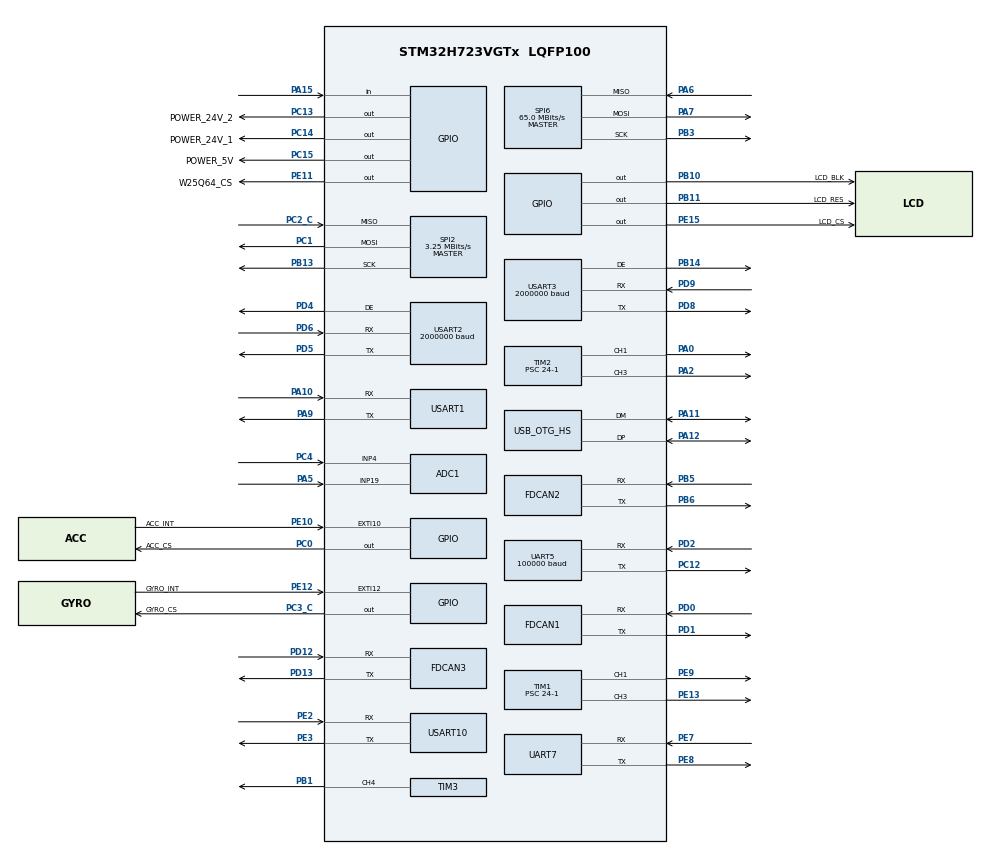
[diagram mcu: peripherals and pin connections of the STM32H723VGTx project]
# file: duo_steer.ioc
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ADC1.Channel-0\#ChannelRegularConversion=ADC_CHANNEL_19
ADC1.Channel-1\#ChannelRegularConversion=ADC_CHANNEL_4
ADC1.ContinuousConvMode=ENABLE
ADC1.ConversionDataManagement=ADC_CONVERSIONDATA_DMA_CIRCULAR
ADC1.NbrOfConversion=2
ADC1.NbrOfConversionFlag=1
ADC1.OffsetNumber-0\#ChannelRegularConversion=ADC_OFFSET_NONE
ADC1.OffsetNumber-1\#ChannelRegularConversion=ADC_OFFSET_NONE
ADC1.OffsetSignedSaturation-0\#ChannelRegularConversion=DISABLE
ADC1.OffsetSignedSaturation-1\#ChannelRegularConversion=DISABLE
ADC1.Rank-0\#ChannelRegularConversion=1
ADC1.Rank-1\#ChannelRegularConversion=2
ADC1.SamplingTime-0\#ChannelRegularConversion=ADC_SAMPLETIME_32CYCLES_5
ADC1.SamplingTime-1\#ChannelRegularConversion=ADC_SAMPLETIME_32CYCLES_5
ADC1.master=1
Bdma.Request0=SPI6_RX
Bdma.Request1=SPI6_TX
Bdma.RequestsNb=2
Bdma.SPI6_RX.0.Direction=DMA_PERIPH_TO_MEMORY
Bdma.SPI6_RX.0.EventEnable=DISABLE
Bdma.SPI6_RX.0.Instance=BDMA_Channel0
Bdma.SPI6_RX.0.MemDataAlignment=DMA_MDATAALIGN_BYTE
Bdma.SPI6_RX.0.MemInc=DMA_MINC_ENABLE
Bdma.SPI6_RX.0.Mode=DMA_NORMAL
Bdma.SPI6_RX.0.PeriphDataAlignment=DMA_PDATAALIGN_BYTE
Bdma.SPI6_RX.0.PeriphInc=DMA_PINC_DISABLE
Bdma.SPI6_RX.0.Polarity=HAL_DMAMUX_REQ_GEN_RISING
Bdma.SPI6_RX.0.Priority=DMA_PRIORITY_LOW
Bdma.SPI6_RX.0.RequestNumber=1
Bdma.SPI6_RX.0.SignalID=NONE
Bdma.SPI6_RX.0.SyncEnable=DISABLE
Bdma.SPI6_RX.0.SyncPolarity=HAL_DMAMUX_SYNC_NO_EVENT
Bdma.SPI6_RX.0.SyncRequestNumber=1
Bdma.SPI6_RX.0.SyncSignalID=NONE
Bdma.SPI6_TX.1.Direction=DMA_MEMORY_TO_PERIPH
Bdma.SPI6_TX.1.EventEnable=DISABLE
Bdma.SPI6_TX.1.Instance=BDMA_Channel1
Bdma.SPI6_TX.1.MemDataAlignment=DMA_MDATAALIGN_BYTE
Bdma.SPI6_TX.1.MemInc=DMA_MINC_ENABLE
Bdma.SPI6_TX.1.Mode=DMA_NORMAL
Bdma.SPI6_TX.1.PeriphDataAlignment=DMA_PDATAALIGN_BYTE
Bdma.SPI6_TX.1.PeriphInc=DMA_PINC_DISABLE
Bdma.SPI6_TX.1.Polarity=HAL_DMAMUX_REQ_GEN_RISING
Bdma.SPI6_TX.1.Priority=DMA_PRIORITY_LOW
Bdma.SPI6_TX.1.RequestNumber=1
Bdma.SPI6_TX.1.SignalID=NONE
Bdma.SPI6_TX.1.SyncEnable=DISABLE
Bdma.SPI6_TX.1.SyncPolarity=HAL_DMAMUX_SYNC_NO_EVENT
Bdma.SPI6_TX.1.SyncRequestNumber=1
Bdma.SPI6_TX.1.SyncSignalID=NONE
CORTEX_M7.CPU_DCache=Enabled
CORTEX_M7.CPU_ICache=Enabled
CORTEX_M7.default_mode_Activation=1
DAC1.DAC_Channel-DAC_OUT2_Int=DAC_CHANNEL_2
Dma.ADC1.0.Direction=DMA_PERIPH_TO_MEMORY
Dma.ADC1.0.EventEnable=DISABLE
Dma.ADC1.0.FIFOMode=DMA_FIFOMODE_DISABLE
Dma.ADC1.0.Instance=DMA1_Stream0
Dma.ADC1.0.MemDataAlignment=DMA_MDATAALIGN_HALFWORD
Dma.ADC1.0.MemInc=DMA_MINC_ENABLE
Dma.ADC1.0.Mode=DMA_CIRCULAR
Dma.ADC1.0.PeriphDataAlignment=DMA_PDATAALIGN_HALFWORD
Dma.ADC1.0.PeriphInc=DMA_PINC_DISABLE
Dma.ADC1.0.Polarity=HAL_DMAMUX_REQ_GEN_RISING
Dma.ADC1.0.Priority=DMA_PRIORITY_LOW
Dma.ADC1.0.RequestNumber=1
Dma.ADC1.0.SignalID=NONE
Dma.ADC1.0.SyncEnable=DISABLE
Dma.ADC1.0.SyncPolarity=HAL_DMAMUX_SYNC_NO_EVENT
Dma.ADC1.0.SyncRequestNumber=1
Dma.ADC1.0.SyncSignalID=NONE
Dma.Request0=ADC1
Dma.Request1=SPI2_RX
Dma.Request10=USART3_RX
Dma.Request11=USART3_TX
Dma.Request12=USART10_RX
Dma.Request13=USART10_TX
Dma.Request2=SPI2_TX
Dma.Request3=UART5_RX
Dma.Request4=UART7_RX
Dma.Request5=UART7_TX
Dma.Request6=USART1_RX
Dma.Request7=USART1_TX
Dma.Request8=USART2_RX
Dma.Request9=USART2_TX
Dma.SPI2_RX.1.Direction=DMA_PERIPH_TO_MEMORY
Dma.SPI2_RX.1.EventEnable=DISABLE
Dma.SPI2_RX.1.FIFOMode=DMA_FIFOMODE_DISABLE
Dma.SPI2_RX.1.Instance=DMA1_Stream1
Dma.SPI2_RX.1.MemDataAlignment=DMA_MDATAALIGN_BYTE
Dma.SPI2_RX.1.MemInc=DMA_MINC_ENABLE
Dma.SPI2_RX.1.Mode=DMA_NORMAL
Dma.SPI2_RX.1.PeriphDataAlignment=DMA_PDATAALIGN_BYTE
Dma.SPI2_RX.1.PeriphInc=DMA_PINC_DISABLE
Dma.SPI2_RX.1.Polarity=HAL_DMAMUX_REQ_GEN_RISING
Dma.SPI2_RX.1.Priority=DMA_PRIORITY_LOW
Dma.SPI2_RX.1.RequestNumber=1
Dma.SPI2_RX.1.SignalID=NONE
Dma.SPI2_RX.1.SyncEnable=DISABLE
Dma.SPI2_RX.1.SyncPolarity=HAL_DMAMUX_SYNC_NO_EVENT
Dma.SPI2_RX.1.SyncRequestNumber=1
Dma.SPI2_RX.1.SyncSignalID=NONE
Dma.SPI2_TX.2.Direction=DMA_MEMORY_TO_PERIPH
Dma.SPI2_TX.2.EventEnable=DISABLE
Dma.SPI2_TX.2.FIFOMode=DMA_FIFOMODE_DISABLE
Dma.SPI2_TX.2.Instance=DMA1_Stream2
Dma.SPI2_TX.2.MemDataAlignment=DMA_MDATAALIGN_BYTE
Dma.SPI2_TX.2.MemInc=DMA_MINC_ENABLE
Dma.SPI2_TX.2.Mode=DMA_NORMAL
Dma.SPI2_TX.2.PeriphDataAlignment=DMA_PDATAALIGN_BYTE
Dma.SPI2_TX.2.PeriphInc=DMA_PINC_DISABLE
Dma.SPI2_TX.2.Polarity=HAL_DMAMUX_REQ_GEN_RISING
Dma.SPI2_TX.2.Priority=DMA_PRIORITY_LOW
Dma.SPI2_TX.2.RequestNumber=1
Dma.SPI2_TX.2.SignalID=NONE
Dma.SPI2_TX.2.SyncEnable=DISABLE
Dma.SPI2_TX.2.SyncPolarity=HAL_DMAMUX_SYNC_NO_EVENT
Dma.SPI2_TX.2.SyncRequestNumber=1
Dma.SPI2_TX.2.SyncSignalID=NONE
Dma.UART5_RX.3.Direction=DMA_PERIPH_TO_MEMORY
Dma.UART5_RX.3.EventEnable=DISABLE
Dma.UART5_RX.3.FIFOMode=DMA_FIFOMODE_DISABLE
Dma.UART5_RX.3.Instance=DMA1_Stream3
Dma.UART5_RX.3.MemDataAlignment=DMA_MDATAALIGN_BYTE
Dma.UART5_RX.3.MemInc=DMA_MINC_ENABLE
Dma.UART5_RX.3.Mode=DMA_CIRCULAR
Dma.UART5_RX.3.PeriphDataAlignment=DMA_PDATAALIGN_BYTE
Dma.UART5_RX.3.PeriphInc=DMA_PINC_DISABLE
Dma.UART5_RX.3.Polarity=HAL_DMAMUX_REQ_GEN_RISING
Dma.UART5_RX.3.Priority=DMA_PRIORITY_LOW
Dma.UART5_RX.3.RequestNumber=1
Dma.UART5_RX.3.SignalID=NONE
Dma.UART5_RX.3.SyncEnable=DISABLE
Dma.UART5_RX.3.SyncPolarity=HAL_DMAMUX_SYNC_NO_EVENT
Dma.UART5_RX.3.SyncRequestNumber=1
Dma.UART5_RX.3.SyncSignalID=NONE
Dma.UART7_RX.4.Direction=DMA_PERIPH_TO_MEMORY
Dma.UART7_RX.4.EventEnable=DISABLE
Dma.UART7_RX.4.FIFOMode=DMA_FIFOMODE_DISABLE
Dma.UART7_RX.4.Instance=DMA1_Stream4
Dma.UART7_RX.4.MemDataAlignment=DMA_MDATAALIGN_BYTE
Dma.UART7_RX.4.MemInc=DMA_MINC_ENABLE
Dma.UART7_RX.4.Mode=DMA_CIRCULAR
Dma.UART7_RX.4.PeriphDataAlignment=DMA_PDATAALIGN_BYTE
Dma.UART7_RX.4.PeriphInc=DMA_PINC_DISABLE
Dma.UART7_RX.4.Polarity=HAL_DMAMUX_REQ_GEN_RISING
Dma.UART7_RX.4.Priority=DMA_PRIORITY_LOW
Dma.UART7_RX.4.RequestNumber=1
Dma.UART7_RX.4.SignalID=NONE
Dma.UART7_RX.4.SyncEnable=DISABLE
Dma.UART7_RX.4.SyncPolarity=HAL_DMAMUX_SYNC_NO_EVENT
Dma.UART7_RX.4.SyncRequestNumber=1
Dma.UART7_RX.4.SyncSignalID=NONE
Dma.UART7_TX.5.Direction=DMA_MEMORY_TO_PERIPH
Dma.UART7_TX.5.EventEnable=DISABLE
Dma.UART7_TX.5.FIFOMode=DMA_FIFOMODE_DISABLE
Dma.UART7_TX.5.Instance=DMA1_Stream5
Dma.UART7_TX.5.MemDataAlignment=DMA_MDATAALIGN_BYTE
Dma.UART7_TX.5.MemInc=DMA_MINC_ENABLE
Dma.UART7_TX.5.Mode=DMA_NORMAL
Dma.UART7_TX.5.PeriphDataAlignment=DMA_PDATAALIGN_BYTE
Dma.UART7_TX.5.PeriphInc=DMA_PINC_DISABLE
Dma.UART7_TX.5.Polarity=HAL_DMAMUX_REQ_GEN_RISING
Dma.UART7_TX.5.Priority=DMA_PRIORITY_LOW
Dma.UART7_TX.5.RequestNumber=1
Dma.UART7_TX.5.SignalID=NONE
Dma.UART7_TX.5.SyncEnable=DISABLE
Dma.UART7_TX.5.SyncPolarity=HAL_DMAMUX_SYNC_NO_EVENT
Dma.UART7_TX.5.SyncRequestNumber=1
Dma.UART7_TX.5.SyncSignalID=NONE
Dma.USART10_RX.12.Direction=DMA_PERIPH_TO_MEMORY
Dma.USART10_RX.12.EventEnable=DISABLE
Dma.USART10_RX.12.FIFOMode=DMA_FIFOMODE_DISABLE
Dma.USART10_RX.12.Instance=DMA2_Stream4
Dma.USART10_RX.12.MemDataAlignment=DMA_MDATAALIGN_BYTE
Dma.USART10_RX.12.MemInc=DMA_MINC_ENABLE
Dma.USART10_RX.12.Mode=DMA_CIRCULAR
Dma.USART10_RX.12.PeriphDataAlignment=DMA_PDATAALIGN_BYTE
Dma.USART10_RX.12.PeriphInc=DMA_PINC_DISABLE
Dma.USART10_RX.12.Polarity=HAL_DMAMUX_REQ_GEN_RISING
Dma.USART10_RX.12.Priority=DMA_PRIORITY_LOW
Dma.USART10_RX.12.RequestNumber=1
Dma.USART10_RX.12.SignalID=NONE
Dma.USART10_RX.12.SyncEnable=DISABLE
Dma.USART10_RX.12.SyncPolarity=HAL_DMAMUX_SYNC_NO_EVENT
Dma.USART10_RX.12.SyncRequestNumber=1
Dma.USART10_RX.12.SyncSignalID=NONE
Dma.USART10_TX.13.Direction=DMA_MEMORY_TO_PERIPH
Dma.USART10_TX.13.EventEnable=DISABLE
Dma.USART10_TX.13.FIFOMode=DMA_FIFOMODE_DISABLE
Dma.USART10_TX.13.Instance=DMA2_Stream5
Dma.USART10_TX.13.MemDataAlignment=DMA_MDATAALIGN_BYTE
Dma.USART10_TX.13.MemInc=DMA_MINC_ENABLE
Dma.USART10_TX.13.Mode=DMA_NORMAL
Dma.USART10_TX.13.PeriphDataAlignment=DMA_PDATAALIGN_BYTE
Dma.USART10_TX.13.PeriphInc=DMA_PINC_DISABLE
Dma.USART10_TX.13.Polarity=HAL_DMAMUX_REQ_GEN_RISING
Dma.USART10_TX.13.Priority=DMA_PRIORITY_LOW
Dma.USART10_TX.13.RequestNumber=1
Dma.USART10_TX.13.SignalID=NONE
Dma.USART10_TX.13.SyncEnable=DISABLE
Dma.USART10_TX.13.SyncPolarity=HAL_DMAMUX_SYNC_NO_EVENT
Dma.USART10_TX.13.SyncRequestNumber=1
Dma.USART10_TX.13.SyncSignalID=NONE
Dma.USART1_RX.6.Direction=DMA_PERIPH_TO_MEMORY
Dma.USART1_RX.6.EventEnable=DISABLE
Dma.USART1_RX.6.FIFOMode=DMA_FIFOMODE_DISABLE
Dma.USART1_RX.6.Instance=DMA1_Stream6
Dma.USART1_RX.6.MemDataAlignment=DMA_MDATAALIGN_BYTE
Dma.USART1_RX.6.MemInc=DMA_MINC_ENABLE
Dma.USART1_RX.6.Mode=DMA_CIRCULAR
Dma.USART1_RX.6.PeriphDataAlignment=DMA_PDATAALIGN_BYTE
Dma.USART1_RX.6.PeriphInc=DMA_PINC_DISABLE
Dma.USART1_RX.6.Polarity=HAL_DMAMUX_REQ_GEN_RISING
Dma.USART1_RX.6.Priority=DMA_PRIORITY_LOW
Dma.USART1_RX.6.RequestNumber=1
Dma.USART1_RX.6.SignalID=NONE
Dma.USART1_RX.6.SyncEnable=DISABLE
Dma.USART1_RX.6.SyncPolarity=HAL_DMAMUX_SYNC_NO_EVENT
Dma.USART1_RX.6.SyncRequestNumber=1
Dma.USART1_RX.6.SyncSignalID=NONE
Dma.USART1_TX.7.Direction=DMA_MEMORY_TO_PERIPH
Dma.USART1_TX.7.EventEnable=DISABLE
Dma.USART1_TX.7.FIFOMode=DMA_FIFOMODE_DISABLE
Dma.USART1_TX.7.Instance=DMA1_Stream7
Dma.USART1_TX.7.MemDataAlignment=DMA_MDATAALIGN_BYTE
Dma.USART1_TX.7.MemInc=DMA_MINC_ENABLE
Dma.USART1_TX.7.Mode=DMA_NORMAL
Dma.USART1_TX.7.PeriphDataAlignment=DMA_PDATAALIGN_BYTE
Dma.USART1_TX.7.PeriphInc=DMA_PINC_DISABLE
Dma.USART1_TX.7.Polarity=HAL_DMAMUX_REQ_GEN_RISING
Dma.USART1_TX.7.Priority=DMA_PRIORITY_LOW
Dma.USART1_TX.7.RequestNumber=1
Dma.USART1_TX.7.SignalID=NONE
Dma.USART1_TX.7.SyncEnable=DISABLE
Dma.USART1_TX.7.SyncPolarity=HAL_DMAMUX_SYNC_NO_EVENT
Dma.USART1_TX.7.SyncRequestNumber=1
Dma.USART1_TX.7.SyncSignalID=NONE
Dma.USART2_RX.8.Direction=DMA_PERIPH_TO_MEMORY
Dma.USART2_RX.8.EventEnable=DISABLE
Dma.USART2_RX.8.FIFOMode=DMA_FIFOMODE_DISABLE
Dma.USART2_RX.8.Instance=DMA2_Stream0
Dma.USART2_RX.8.MemDataAlignment=DMA_MDATAALIGN_BYTE
Dma.USART2_RX.8.MemInc=DMA_MINC_ENABLE
Dma.USART2_RX.8.Mode=DMA_CIRCULAR
Dma.USART2_RX.8.PeriphDataAlignment=DMA_PDATAALIGN_BYTE
Dma.USART2_RX.8.PeriphInc=DMA_PINC_DISABLE
Dma.USART2_RX.8.Polarity=HAL_DMAMUX_REQ_GEN_RISING
Dma.USART2_RX.8.Priority=DMA_PRIORITY_LOW
Dma.USART2_RX.8.RequestNumber=1
Dma.USART2_RX.8.SignalID=NONE
Dma.USART2_RX.8.SyncEnable=DISABLE
Dma.USART2_RX.8.SyncPolarity=HAL_DMAMUX_SYNC_NO_EVENT
Dma.USART2_RX.8.SyncRequestNumber=1
Dma.USART2_RX.8.SyncSignalID=NONE
Dma.USART2_TX.9.Direction=DMA_MEMORY_TO_PERIPH
Dma.USART2_TX.9.EventEnable=DISABLE
Dma.USART2_TX.9.FIFOMode=DMA_FIFOMODE_DISABLE
Dma.USART2_TX.9.Instance=DMA2_Stream1
Dma.USART2_TX.9.MemDataAlignment=DMA_MDATAALIGN_BYTE
Dma.USART2_TX.9.MemInc=DMA_MINC_ENABLE
Dma.USART2_TX.9.Mode=DMA_NORMAL
Dma.USART2_TX.9.PeriphDataAlignment=DMA_PDATAALIGN_BYTE
Dma.USART2_TX.9.PeriphInc=DMA_PINC_DISABLE
Dma.USART2_TX.9.Polarity=HAL_DMAMUX_REQ_GEN_RISING
Dma.USART2_TX.9.Priority=DMA_PRIORITY_LOW
Dma.USART2_TX.9.RequestNumber=1
Dma.USART2_TX.9.SignalID=NONE
Dma.USART2_TX.9.SyncEnable=DISABLE
Dma.USART2_TX.9.SyncPolarity=HAL_DMAMUX_SYNC_NO_EVENT
Dma.USART2_TX.9.SyncRequestNumber=1
Dma.USART2_TX.9.SyncSignalID=NONE
Dma.USART3_RX.10.Direction=DMA_PERIPH_TO_MEMORY
Dma.USART3_RX.10.EventEnable=DISABLE
Dma.USART3_RX.10.FIFOMode=DMA_FIFOMODE_DISABLE
Dma.USART3_RX.10.Instance=DMA2_Stream2
Dma.USART3_RX.10.MemDataAlignment=DMA_MDATAALIGN_BYTE
Dma.USART3_RX.10.MemInc=DMA_MINC_ENABLE
Dma.USART3_RX.10.Mode=DMA_CIRCULAR
Dma.USART3_RX.10.PeriphDataAlignment=DMA_PDATAALIGN_BYTE
Dma.USART3_RX.10.PeriphInc=DMA_PINC_DISABLE
Dma.USART3_RX.10.Polarity=HAL_DMAMUX_REQ_GEN_RISING
Dma.USART3_RX.10.Priority=DMA_PRIORITY_LOW
Dma.USART3_RX.10.RequestNumber=1
Dma.USART3_RX.10.SignalID=NONE
Dma.USART3_RX.10.SyncEnable=DISABLE
Dma.USART3_RX.10.SyncPolarity=HAL_DMAMUX_SYNC_NO_EVENT
Dma.USART3_RX.10.SyncRequestNumber=1
Dma.USART3_RX.10.SyncSignalID=NONE
Dma.USART3_TX.11.Direction=DMA_MEMORY_TO_PERIPH
Dma.USART3_TX.11.EventEnable=DISABLE
Dma.USART3_TX.11.FIFOMode=DMA_FIFOMODE_DISABLE
Dma.USART3_TX.11.Instance=DMA2_Stream3
Dma.USART3_TX.11.MemDataAlignment=DMA_MDATAALIGN_BYTE
Dma.USART3_TX.11.MemInc=DMA_MINC_ENABLE
Dma.USART3_TX.11.Mode=DMA_NORMAL
Dma.USART3_TX.11.PeriphDataAlignment=DMA_PDATAALIGN_BYTE
Dma.USART3_TX.11.PeriphInc=DMA_PINC_DISABLE
Dma.USART3_TX.11.Polarity=HAL_DMAMUX_REQ_GEN_RISING
Dma.USART3_TX.11.Priority=DMA_PRIORITY_LOW
Dma.USART3_TX.11.RequestNumber=1
Dma.USART3_TX.11.SignalID=NONE
Dma.USART3_TX.11.SyncEnable=DISABLE
Dma.USART3_TX.11.SyncPolarity=HAL_DMAMUX_SYNC_NO_EVENT
Dma.USART3_TX.11.SyncRequestNumber=1
Dma.USART3_TX.11.SyncSignalID=NONE
FDCAN1.CalculateBaudRateNominal=2166666
FDCAN1.CalculateTimeBitNominal=461
FDCAN1.CalculateTimeQuantumNominal=153.84615384615384
FDCAN2.CalculateBaudRateNominal=2166666
FDCAN2.CalculateTimeBitNominal=461
FDCAN2.CalculateTimeQuantumNominal=153.84615384615384
FDCAN3.CalculateBaudRateNominal=2166666
FDCAN3.CalculateTimeBitNominal=461
FDCAN3.CalculateTimeQuantumNominal=153.84615384615384
FREERTOS.Tasks01=defaultTask,24,512,StartDefaultTask,Default,NULL,Dynamic,NULL,NULL;dr16,24,1024,dr16_task,As weak,NULL,Dynamic,NULL,NULL;vt13,24,1024,vt13_task,As weak,NULL,Dynamic,NULL,NULL;gimbal,24,2048,gimbal_task,As weak,NULL,Dynamic,NULL,NULL;chassis,8,1024,chassis_task,As weak,NULL,Dynamic,NULL,NULL;shoot,15,1024,shoot_task,As weak,NULL,Dynamic,NULL,NULL;super_power,23,1024,super_power_task,As weak,NULL,Dynamic,NULL,NULL;version,40,1024,version_task,As weak,NULL,Dynamic,NULL,NULL;imu,40,1024,imu_task,As weak,NULL,Dynamic,NULL,NULL;imu_fdcan,24,1024,imu_fdcan_task,As weak,NULL,Dynamic,NULL,NULL;imu_rs485,24,1024,imu_485_task,As weak,NULL,Dynamic,NULL,NULL
FREERTOS.configCHECK_FOR_STACK_OVERFLOW=2
FREERTOS.configTOTAL_HEAP_SIZE=65535
FREERTOS.configUSE_MALLOC_FAILED_HOOK=1
Mcu.Family=STM32H7
Mcu.Name=STM32H723VGTx
Mcu.Package=LQFP100
NVIC.ADC_IRQn=true\:5\:0\:false\:false\:true\:true\:true\:true\:true
NVIC.BDMA_Channel0_IRQn=true\:5\:0\:false\:false\:true\:true\:false\:true\:true
NVIC.BDMA_Channel1_IRQn=true\:5\:0\:false\:false\:true\:true\:false\:true\:true
NVIC.DMA1_Stream0_IRQn=true\:5\:0\:false\:false\:true\:true\:false\:true\:true
NVIC.DMA1_Stream1_IRQn=true\:5\:0\:false\:false\:true\:true\:false\:true\:true
NVIC.DMA1_Stream2_IRQn=true\:5\:0\:false\:false\:true\:true\:false\:true\:true
NVIC.DMA1_Stream3_IRQn=true\:5\:0\:false\:false\:true\:true\:false\:true\:true
NVIC.DMA1_Stream4_IRQn=true\:5\:0\:false\:false\:true\:true\:false\:true\:true
NVIC.DMA1_Stream5_IRQn=true\:5\:0\:false\:false\:true\:true\:false\:true\:true
NVIC.DMA1_Stream6_IRQn=true\:5\:0\:false\:false\:true\:true\:false\:true\:true
NVIC.DMA1_Stream7_IRQn=true\:5\:0\:false\:false\:true\:true\:false\:true\:true
NVIC.DMA2_Stream0_IRQn=true\:5\:0\:false\:false\:true\:true\:false\:true\:true
NVIC.DMA2_Stream1_IRQn=true\:5\:0\:false\:false\:true\:true\:false\:true\:true
NVIC.DMA2_Stream2_IRQn=true\:5\:0\:false\:false\:true\:true\:false\:true\:true
NVIC.DMA2_Stream3_IRQn=true\:5\:0\:false\:false\:true\:true\:false\:true\:true
NVIC.DMA2_Stream4_IRQn=true\:5\:0\:false\:false\:true\:true\:false\:true\:true
NVIC.DMA2_Stream5_IRQn=true\:5\:0\:false\:false\:true\:true\:false\:true\:true
NVIC.EXTI15_10_IRQn=true\:5\:0\:false\:false\:true\:true\:true\:true\:true
NVIC.FDCAN1_IT0_IRQn=true\:5\:0\:false\:false\:true\:true\:true\:true\:true
NVIC.FDCAN1_IT1_IRQn=true\:5\:0\:false\:false\:true\:true\:true\:true\:true
NVIC.FDCAN2_IT0_IRQn=true\:5\:0\:false\:false\:true\:true\:true\:true\:true
NVIC.FDCAN2_IT1_IRQn=true\:5\:0\:false\:false\:true\:true\:true\:true\:true
NVIC.FDCAN3_IT0_IRQn=true\:5\:0\:false\:false\:true\:true\:true\:true\:true
NVIC.FDCAN3_IT1_IRQn=true\:5\:0\:false\:false\:true\:true\:true\:true\:true
NVIC.OTG_HS_IRQn=true\:5\:0\:false\:false\:true\:true\:true\:true\:true
NVIC.PriorityGroup=NVIC_PRIORITYGROUP_4
NVIC.SPI2_IRQn=true\:5\:0\:false\:false\:true\:true\:false\:true\:true
NVIC.SPI6_IRQn=true\:5\:0\:false\:false\:true\:true\:true\:true\:true
NVIC.TIM4_IRQn=true\:0\:0\:true\:false\:true\:false\:false\:true\:true
NVIC.TimeBase=TIM4_IRQn
NVIC.TimeBaseIP=TIM4
NVIC.UART5_IRQn=true\:5\:0\:false\:false\:true\:true\:true\:true\:true
NVIC.UART7_IRQn=true\:5\:0\:false\:false\:true\:true\:false\:true\:true
NVIC.USART10_IRQn=true\:5\:0\:false\:false\:true\:true\:false\:true\:true
NVIC.USART1_IRQn=true\:5\:0\:false\:false\:true\:true\:true\:true\:true
NVIC.USART2_IRQn=true\:5\:0\:false\:false\:true\:true\:false\:true\:true
NVIC.USART3_IRQn=true\:5\:0\:false\:false\:true\:true\:false\:true\:true
PA0.Signal=S_TIM2_CH1_ETR
PA10.Mode=Asynchronous
PA10.Signal=USART1_RX
PA11.Mode=Device_Only_FS
PA11.Signal=USB_OTG_HS_DM
PA12.Mode=Device_Only_FS
PA12.Signal=USB_OTG_HS_DP
PA13(JTMS/SWDIO).Mode=Serial_Wire
PA13(JTMS/SWDIO).Signal=DEBUG_JTMS-SWDIO
PA14(JTCK/SWCLK).Mode=Serial_Wire
PA14(JTCK/SWCLK).Signal=DEBUG_JTCK-SWCLK
PA15(JTDI).Signal=GPIO_Input
PA2.Signal=S_TIM2_CH3
PA5.Signal=ADCx_INP19
PA6.Mode=Full_Duplex_Master
PA6.Signal=SPI6_MISO
PA7.Mode=Full_Duplex_Master
PA7.Signal=SPI6_MOSI
PA9.Mode=Asynchronous
PA9.Signal=USART1_TX
PB1.Signal=S_TIM3_CH4
PB10.GPIO_Label=LCD_BLK
PB10.Signal=GPIO_Output
PB11.GPIO_Label=LCD_RES
PB11.Signal=GPIO_Output
PB13.Mode=Full_Duplex_Master
PB13.Signal=SPI2_SCK
PB14.Mode=Hardware Flow Control (RS485)
PB14.Signal=USART3_DE
PB15.Signal=S_TIM12_CH2
PB3(JTDO/TRACESWO).Mode=Full_Duplex_Master
PB3(JTDO/TRACESWO).Signal=SPI6_SCK
PB5.Mode=FDCAN_Activate
PB5.Signal=FDCAN2_RX
PB6.Mode=FDCAN_Activate
PB6.Signal=FDCAN2_TX
PC0.GPIO_Label=ACC_CS
PC0.Signal=GPIO_Output
PC1.Mode=Full_Duplex_Master
PC1.Signal=SPI2_MOSI
PC12.Mode=Asynchronous
PC12.Signal=UART5_TX
PC13.GPIO_Label=POWER_24V_2
PC13.Signal=GPIO_Output
PC14-OSC32_IN.GPIO_Label=POWER_24V_1
PC14-OSC32_IN.Signal=GPIO_Output
PC15-OSC32_OUT.GPIO_Label=POWER_5V
PC15-OSC32_OUT.Signal=GPIO_Output
PC2_C.Mode=Full_Duplex_Master
PC2_C.Signal=SPI2_MISO
PC3_C.GPIO_Label=GYRO_CS
PC3_C.Signal=GPIO_Output
PC4.Signal=ADCx_INP4
PD0.Mode=FDCAN_Activate
PD0.Signal=FDCAN1_RX
PD1.Mode=FDCAN_Activate
PD1.Signal=FDCAN1_TX
PD12.Mode=FDCAN_Activate
PD12.Signal=FDCAN3_RX
PD13.Mode=FDCAN_Activate
PD13.Signal=FDCAN3_TX
PD2.Mode=Asynchronous
PD2.Signal=UART5_RX
PD4.Mode=Hardware Flow Control (RS485)
PD4.Signal=USART2_DE
PD5.Mode=Asynchronous
PD5.Signal=USART2_TX
PD6.Mode=Asynchronous
PD6.Signal=USART2_RX
PD8.Mode=Asynchronous
PD8.Signal=USART3_TX
PD9.Mode=Asynchronous
PD9.Signal=USART3_RX
PE10.GPIO_Label=ACC_INT
PE10.Signal=GPXTI10
PE11.GPIO_Label=W25Q64_CS
PE11.Signal=GPIO_Output
PE12.GPIO_Label=GYRO_INT
PE12.Signal=GPXTI12
PE13.Signal=S_TIM1_CH3
PE15.GPIO_Label=LCD_CS
PE15.Signal=GPIO_Output
PE2.Mode=Asynchronous
PE2.Signal=USART10_RX
PE3.Mode=Asynchronous
PE3.Signal=USART10_TX
PE7.Mode=Asynchronous
PE7.Signal=UART7_RX
PE8.Mode=Asynchronous
PE8.Signal=UART7_TX
PE9.Signal=S_TIM1_CH1
PH0-OSC_IN.Mode=HSE-External-Oscillator
PH0-OSC_IN.Signal=RCC_OSC_IN
PH1-OSC_OUT.Mode=HSE-External-Oscillator
PH1-OSC_OUT.Signal=RCC_OSC_OUT
ProjectManager.HeapSize=0x200
ProjectManager.StackSize=0x400
ProjectManager.TargetToolchain=CMake
RCC.ADCFreq_Value=96000000
RCC.APB1Freq_Value=130000000
RCC.APB2Freq_Value=130000000
RCC.APB3Freq_Value=130000000
RCC.APB4Freq_Value=130000000
RCC.CortexFreq_Value=520000000
RCC.D1PPRE=RCC_APB3_DIV2
RCC.D2PPRE1=RCC_APB1_DIV2
RCC.D2PPRE2=RCC_APB2_DIV2
RCC.D3PPRE=RCC_APB4_DIV2
RCC.DIVM1=3
RCC.DIVM2=2
RCC.DIVN1=65
RCC.DIVN2=16
RCC.DIVP1=1
RCC.DIVQ1=5
RCC.HCLKFreq_Value=260000000
RCC.HPRE=RCC_HCLK_DIV2
RCC.HSE_VALUE=24000000
RCC.PLL2FRACN=0
RCC.PLLFRACN=0
RCC.PLLSourceVirtual=RCC_PLLSOURCE_HSE
RCC.SYSCLKFreq_VALUE=520000000
RCC.SYSCLKSource=RCC_SYSCLKSOURCE_PLLCLK
RCC.USBCLockSelection=RCC_USBCLKSOURCE_HSI48
RCC.USBFreq_Value=48000000
SH.ADCx_INP19.0=ADC1_INP19,IN19-Single-Ended
SH.ADCx_INP4.0=ADC1_INP4,IN4-Single-Ended
SH.S_TIM12_CH2.0=TIM12_CH2
SH.S_TIM1_CH1.0=TIM1_CH1,PWM Generation1 CH1
SH.S_TIM1_CH3.0=TIM1_CH3,PWM Generation3 CH3
SH.S_TIM2_CH1_ETR.0=TIM2_CH1,PWM Generation1 CH1
SH.S_TIM2_CH3.0=TIM2_CH3,PWM Generation3 CH3
SH.S_TIM3_CH4.0=TIM3_CH4,PWM Generation4 CH4
SPI2.BaudRatePrescaler=SPI_BAUDRATEPRESCALER_32
SPI2.CLKPhase=SPI_PHASE_2EDGE
SPI2.CLKPolarity=SPI_POLARITY_HIGH
SPI2.CalculateBaudRate=3.25 MBits/s
SPI2.DataSize=SPI_DATASIZE_8BIT
SPI2.Direction=SPI_DIRECTION_2LINES
SPI2.Mode=SPI_MODE_MASTER
SPI2.VirtualType=VM_MASTER
SPI6.CLKPhase=SPI_PHASE_2EDGE
SPI6.CalculateBaudRate=65.0 MBits/s
SPI6.DataSize=SPI_DATASIZE_8BIT
SPI6.Direction=SPI_DIRECTION_2LINES
SPI6.Mode=SPI_MODE_MASTER
SPI6.VirtualType=VM_MASTER
STMicroelectronics.X-CUBE-ALGOBUILD.1.5.0.LibraryCcDSPOoLibraryJjDSPOoLibrary=true
TIM1.AutoReloadPreload=TIM_AUTORELOAD_PRELOAD_ENABLE
TIM1.Channel-PWM\ Generation1\ CH1=TIM_CHANNEL_1
TIM1.Channel-PWM\ Generation3\ CH3=TIM_CHANNEL_3
TIM1.Period=10000-1
TIM1.Prescaler=24-1
TIM1.Pulse-PWM\ Generation1\ CH1=5000
TIM1.Pulse-PWM\ Generation3\ CH3=5000
TIM2.Channel-PWM\ Generation1\ CH1=TIM_CHANNEL_1
TIM2.Channel-PWM\ Generation3\ CH3=TIM_CHANNEL_3
TIM2.Period=10000-1
TIM2.Prescaler=24-1
TIM2.Pulse-PWM\ Generation1\ CH1=500
TIM2.Pulse-PWM\ Generation3\ CH3=500
TIM3.Channel-PWM\ Generation4\ CH4=TIM_CHANNEL_4
TIM3.Period=10000-1
TIM3.Prescaler=24-1
UART5.BaudRate=100000
UART5.Mode=MODE_RX
UART5.Parity=PARITY_EVEN
UART5.WordLength=WORDLENGTH_9B
USART1.VirtualMode-Asynchronous=VM_ASYNC
USART10.VirtualMode=VM_ASYNC
USART2.BaudRate=2000000
USART2.VirtualMode-Asynchronous=VM_ASYNC
USART2.VirtualMode-Hardware\ Flow\ Control\ (RS485)=VM_ASYNC
USART3.BaudRate=2000000
USART3.VirtualMode-Asynchronous=VM_ASYNC
USART3.VirtualMode-Hardware\ Flow\ Control\ (RS485)=VM_ASYNC
USB_OTG_HS.VirtualMode-Device_Only_FS=Device_Only_FS
USB_OTG_HS.dma_enable-Device_Only_FS=ENABLE
VP_DAC1_VS_DACI2.Mode=DAC_OUT2_Int
VP_FREERTOS_VS_CMSIS_V2.Mode=CMSIS_V2
VP_MEMORYMAP_VS_MEMORYMAP.Mode=CurAppReg
VP_STMicroelectronics.X-CUBE-ALGOBUILD_VS_DSPOoLibraryJjLibrary_1.5.0_1.5.0.Mode=DSPOoLibraryJjLibrary
VP_SYS_VS_tim4.Mode=TIM4
board=custom

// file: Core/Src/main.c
/* USER CODE BEGIN Header */
/**
  ******************************************************************************
  * @file           : main.c
  * @brief          : Main program body
  ******************************************************************************
  * @attention
  *
  * Copyright (c) 2026 STMicroelectronics.
  * All rights reserved.
  *
  * This software is licensed under terms that can be found in the LICENSE file
  * in the root directory of this software component.
  * If no LICENSE file comes with this software, it is provided AS-IS.
  *
  ******************************************************************************
  */
/* USER CODE END Header */
#include "main.h"
#include "FreeRTOS.h"
#include "cmsis_os2.h"
#include "adc.h"
#include "bdma.h"
#include "dac.h"
#include "dma.h"
#include "fdcan.h"
#include "spi.h"
#include "tim.h"
#include "usart.h"
#include "usb_otg.h"
#include "gpio.h"

void SystemClock_Config(void);
static void MPU_Config(void);
void MX_FREERTOS_Init(void);

int main(void)
{

  /* MPU Configuration--------------------------------------------------------*/
  MPU_Config();

  /* Enable the CPU Cache */

  /* Enable I-Cache---------------------------------------------------------*/
  SCB_EnableICache();

  /* Enable D-Cache---------------------------------------------------------*/
  SCB_EnableDCache();

  /* MCU Configuration--------------------------------------------------------*/

  /* Reset of all peripherals, Initializes the Flash interface and the Systick. */
  HAL_Init();

  /* Configure the system clock */
  SystemClock_Config();

  /* Initialize all configured peripherals */
  MX_GPIO_Init();
  MX_DMA_Init();
  MX_BDMA_Init();
  MX_ADC1_Init();
  MX_FDCAN1_Init();
  MX_FDCAN2_Init();
  MX_FDCAN3_Init();
  MX_USB_OTG_HS_PCD_Init();
  MX_DAC1_Init();
  MX_SPI2_Init();
  MX_TIM1_Init();
  MX_TIM3_Init();
  MX_SPI6_Init();
  MX_TIM2_Init();
  MX_UART5_Init();
  MX_UART7_Init();
  MX_USART1_UART_Init();
  MX_USART2_UART_Init();
  MX_USART3_UART_Init();
  MX_USART10_UART_Init();

  /* Init scheduler */
  osKernelInitialize();  /* Call init function for freertos objects (in cmsis_os2.c) */
  MX_FREERTOS_Init();

  /* Start scheduler */
  osKernelStart();

  /* We should never get here as control is now taken by the scheduler */

  /* Infinite loop */
  while (1)
  {

  }
}

void SystemClock_Config(void)
{
  RCC_OscInitTypeDef RCC_OscInitStruct = {0};
  RCC_ClkInitTypeDef RCC_ClkInitStruct = {0};

  /** Supply configuration update enable
  */
  HAL_PWREx_ConfigSupply(PWR_LDO_SUPPLY);

  /** Configure the main internal regulator output voltage
  */
  __HAL_PWR_VOLTAGESCALING_CONFIG(PWR_REGULATOR_VOLTAGE_SCALE0);

  while(!__HAL_PWR_GET_FLAG(PWR_FLAG_VOSRDY)) {}

  /** Initializes the RCC Oscillators according to the specified parameters
  * in the RCC_OscInitTypeDef structure.
  */
  RCC_OscInitStruct.OscillatorType = RCC_OSCILLATORTYPE_HSI48|RCC_OSCILLATORTYPE_HSE;
  RCC_OscInitStruct.HSEState = RCC_HSE_ON;
  RCC_OscInitStruct.HSI48State = RCC_HSI48_ON;
  RCC_OscInitStruct.PLL.PLLState = RCC_PLL_ON;
  RCC_OscInitStruct.PLL.PLLSource = RCC_PLLSOURCE_HSE;
  RCC_OscInitStruct.PLL.PLLM = 3;
  RCC_OscInitStruct.PLL.PLLN = 65;
  RCC_OscInitStruct.PLL.PLLP = 1;
  RCC_OscInitStruct.PLL.PLLQ = 5;
  RCC_OscInitStruct.PLL.PLLR = 2;
  RCC_OscInitStruct.PLL.PLLRGE = RCC_PLL1VCIRANGE_3;
  RCC_OscInitStruct.PLL.PLLVCOSEL = RCC_PLL1VCOWIDE;
  RCC_OscInitStruct.PLL.PLLFRACN = 0;
  if (HAL_RCC_OscConfig(&RCC_OscInitStruct) != HAL_OK)
  {
    Error_Handler();
  }

  /** Initializes the CPU, AHB and APB buses clocks
  */
  RCC_ClkInitStruct.ClockType = RCC_CLOCKTYPE_HCLK|RCC_CLOCKTYPE_SYSCLK
                              |RCC_CLOCKTYPE_PCLK1|RCC_CLOCKTYPE_PCLK2
                              |RCC_CLOCKTYPE_D3PCLK1|RCC_CLOCKTYPE_D1PCLK1;
  RCC_ClkInitStruct.SYSCLKSource = RCC_SYSCLKSOURCE_PLLCLK;
  RCC_ClkInitStruct.SYSCLKDivider = RCC_SYSCLK_DIV1;
  RCC_ClkInitStruct.AHBCLKDivider = RCC_HCLK_DIV2;
  RCC_ClkInitStruct.APB3CLKDivider = RCC_APB3_DIV2;
  RCC_ClkInitStruct.APB1CLKDivider = RCC_APB1_DIV2;
  RCC_ClkInitStruct.APB2CLKDivider = RCC_APB2_DIV2;
  RCC_ClkInitStruct.APB4CLKDivider = RCC_APB4_DIV2;

  if (HAL_RCC_ClockConfig(&RCC_ClkInitStruct, FLASH_LATENCY_3) != HAL_OK)
  {
    Error_Handler();
  }
}

 /* MPU Configuration */

void MPU_Config(void)
{
  MPU_Region_InitTypeDef MPU_InitStruct = {0};

  /* Disables the MPU */
  HAL_MPU_Disable();

  /** Initializes and configures the Region and the memory to be protected
  */
  MPU_InitStruct.Enable = MPU_REGION_ENABLE;
  MPU_InitStruct.Number = MPU_REGION_NUMBER0;
  MPU_InitStruct.BaseAddress = 0x0;
  MPU_InitStruct.Size = MPU_REGION_SIZE_4GB;
  MPU_InitStruct.SubRegionDisable = 0x87;
  MPU_InitStruct.TypeExtField = MPU_TEX_LEVEL0;
  MPU_InitStruct.AccessPermission = MPU_REGION_NO_ACCESS;
  MPU_InitStruct.DisableExec = MPU_INSTRUCTION_ACCESS_DISABLE;
  MPU_InitStruct.IsShareable = MPU_ACCESS_SHAREABLE;
  MPU_InitStruct.IsCacheable = MPU_ACCESS_NOT_CACHEABLE;
  MPU_InitStruct.IsBufferable = MPU_ACCESS_NOT_BUFFERABLE;

  HAL_MPU_ConfigRegion(&MPU_InitStruct);
  /* Enables the MPU */
  HAL_MPU_Enable(MPU_PRIVILEGED_DEFAULT);

}

void HAL_TIM_PeriodElapsedCallback(TIM_HandleTypeDef *htim)
{
  if (htim->Instance == TIM4)
  {
    HAL_IncTick();
  }
}

void Error_Handler(void)
{
  __disable_irq();
  while (1)
  {
  }
}

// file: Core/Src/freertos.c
/* USER CODE BEGIN Header */
/**
  ******************************************************************************
  * File Name          : freertos.c
  * Description        : Code for freertos applications
  ******************************************************************************
  * @attention
  *
  * Copyright (c) 2026 STMicroelectronics.
  * All rights reserved.
  *
  * This software is licensed under terms that can be found in the LICENSE file
  * in the root directory of this software component.
  * If no LICENSE file comes with this software, it is provided AS-IS.
  *
  ******************************************************************************
  */
/* USER CODE END Header */

#include "FreeRTOS.h"
#include "task.h"
#include "main.h"
#include "FreeRTOS.h"
#include "cmsis_os2.h"

/* USER CODE BEGIN Includes */
#include <stdalign.h>
/* USER CODE END Includes */

/* USER CODE BEGIN Variables */
/* FreeRTOS 动态堆放到 .axi_ram (RAM_D1, 320KB)，释放 64KB DTCM 空间。 */
alignas(8) uint8_t ucHeap[configTOTAL_HEAP_SIZE] __attribute__((section(".axi_ram")));
/* USER CODE END Variables */
/* Definitions for defaultTask */
osThreadId_t defaultTaskHandle;
const osThreadAttr_t defaultTask_attributes = {
  .name = "defaultTask",
  .stack_size = 512 * 4,
  .priority = (osPriority_t) osPriorityNormal,
};
/* Definitions for dr16 */
osThreadId_t dr16Handle;
const osThreadAttr_t dr16_attributes = {
  .name = "dr16",
  .stack_size = 1024 * 4,
  .priority = (osPriority_t) osPriorityNormal,
};
/* Definitions for vt13 */
osThreadId_t vt13Handle;
const osThreadAttr_t vt13_attributes = {
  .name = "vt13",
  .stack_size = 1024 * 4,
  .priority = (osPriority_t) osPriorityNormal,
};
/* Definitions for gimbal */
osThreadId_t gimbalHandle;
const osThreadAttr_t gimbal_attributes = {
  .name = "gimbal",
  .stack_size = 2048 * 4,
  .priority = (osPriority_t) osPriorityNormal,
};
/* Definitions for chassis */
osThreadId_t chassisHandle;
const osThreadAttr_t chassis_attributes = {
  .name = "chassis",
  .stack_size = 1024 * 4,
  .priority = (osPriority_t) osPriorityLow,
};
/* Definitions for shoot */
osThreadId_t shootHandle;
const osThreadAttr_t shoot_attributes = {
  .name = "shoot",
  .stack_size = 1024 * 4,
  .priority = (osPriority_t) osPriorityLow7,
};
/* Definitions for super_power */
osThreadId_t super_powerHandle;
const osThreadAttr_t super_power_attributes = {
  .name = "super_power",
  .stack_size = 1024 * 4,
  .priority = (osPriority_t) osPriorityBelowNormal7,
};
/* Definitions for version */
osThreadId_t versionHandle;
const osThreadAttr_t version_attributes = {
  .name = "version",
  .stack_size = 1024 * 4,
  .priority = (osPriority_t) osPriorityHigh,
};
/* Definitions for imu */
osThreadId_t imuHandle;
const osThreadAttr_t imu_attributes = {
  .name = "imu",
  .stack_size = 1024 * 4,
  .priority = (osPriority_t) osPriorityHigh,
};
/* Definitions for imu_fdcan */
osThreadId_t imu_fdcanHandle;
const osThreadAttr_t imu_fdcan_attributes = {
  .name = "imu_fdcan",
  .stack_size = 1024 * 4,
  .priority = (osPriority_t) osPriorityNormal,
};
/* Definitions for imu_rs485 */
osThreadId_t imu_rs485Handle;
const osThreadAttr_t imu_rs485_attributes = {
  .name = "imu_rs485",
  .stack_size = 1024 * 4,
  .priority = (osPriority_t) osPriorityNormal,
};

void StartDefaultTask(void *argument);
void dr16_task(void *argument);
void vt13_task(void *argument);
void gimbal_task(void *argument);
void chassis_task(void *argument);
void shoot_task(void *argument);
void super_power_task(void *argument);
void version_task(void *argument);
void imu_task(void *argument);
void imu_fdcan_task(void *argument);
void imu_485_task(void *argument);

void MX_FREERTOS_Init(void); /* (MISRA C 2004 rule 8.1) */

/* Hook prototypes */
void vApplicationStackOverflowHook(xTaskHandle xTask, char *pcTaskName);
void vApplicationMallocFailedHook(void);

/* USER CODE BEGIN 4 */
void vApplicationStackOverflowHook(xTaskHandle xTask, char *pcTaskName)
{
   /* Run time stack overflow checking is performed if
   configCHECK_FOR_STACK_OVERFLOW is defined to 1 or 2. This hook function is
   called if a stack overflow is detected. */
}
/* USER CODE END 4 */

/* USER CODE BEGIN 5 */
void vApplicationMallocFailedHook(void)
{
   /* vApplicationMallocFailedHook() will only be called if
   configUSE_MALLOC_FAILED_HOOK is set to 1 in FreeRTOSConfig.h. It is a hook
   function that will get called if a call to pvPortMalloc() fails.
   pvPortMalloc() is called internally by the kernel whenever a task, queue,
   timer or semaphore is created. It is also called by various parts of the
   demo application. If heap_1.c or heap_2.c are used, then the size of the
   heap available to pvPortMalloc() is defined by configTOTAL_HEAP_SIZE in
   FreeRTOSConfig.h, and the xPortGetFreeHeapSize() API function can be used
   to query the size of free heap space that remains (although it does not
   provide information on how the remaining heap might be fragmented). */
}
/* USER CODE END 5 */

void MX_FREERTOS_Init(void) {

  /* Create the thread(s) */
  /* creation of defaultTask */
  defaultTaskHandle = osThreadNew(StartDefaultTask, NULL, &defaultTask_attributes);

  /* creation of dr16 */
  dr16Handle = osThreadNew(dr16_task, NULL, &dr16_attributes);

  /* creation of vt13 */
  vt13Handle = osThreadNew(vt13_task, NULL, &vt13_attributes);

  /* creation of gimbal */
  gimbalHandle = osThreadNew(gimbal_task, NULL, &gimbal_attributes);

  /* creation of chassis */
  chassisHandle = osThreadNew(chassis_task, NULL, &chassis_attributes);

  /* creation of shoot */
  shootHandle = osThreadNew(shoot_task, NULL, &shoot_attributes);

  /* creation of super_power */
  super_powerHandle = osThreadNew(super_power_task, NULL, &super_power_attributes);

  /* creation of version */
  versionHandle = osThreadNew(version_task, NULL, &version_attributes);

  /* creation of imu */
  imuHandle = osThreadNew(imu_task, NULL, &imu_attributes);

  /* creation of imu_fdcan */
  imu_fdcanHandle = osThreadNew(imu_fdcan_task, NULL, &imu_fdcan_attributes);

  /* creation of imu_rs485 */
  imu_rs485Handle = osThreadNew(imu_485_task, NULL, &imu_rs485_attributes);

}

void StartDefaultTask(void *argument)
{
  for(;;)
  {
    osDelay(1);
  }
}

__weak void dr16_task(void *argument)
{
  for(;;)
  {
    osDelay(1);
  }
}

__weak void vt13_task(void *argument)
{
  for(;;)
  {
    osDelay(1);
  }
}

__weak void gimbal_task(void *argument)
{
  for(;;)
  {
    osDelay(1);
  }
}

__weak void chassis_task(void *argument)
{
  for(;;)
  {
    osDelay(1);
  }
}

__weak void shoot_task(void *argument)
{
  for(;;)
  {
    osDelay(1);
  }
}

__weak void super_power_task(void *argument)
{
  for(;;)
  {
    osDelay(1);
  }
}

__weak void version_task(void *argument)
{
  for(;;)
  {
    osDelay(1);
  }
}

__weak void imu_task(void *argument)
{
  for(;;)
  {
    osDelay(1);
  }
}

__weak void imu_fdcan_task(void *argument)
{
  for(;;)
  {
    osDelay(1);
  }
}

__weak void imu_485_task(void *argument)
{
  for(;;)
  {
    osDelay(1);
  }
}
